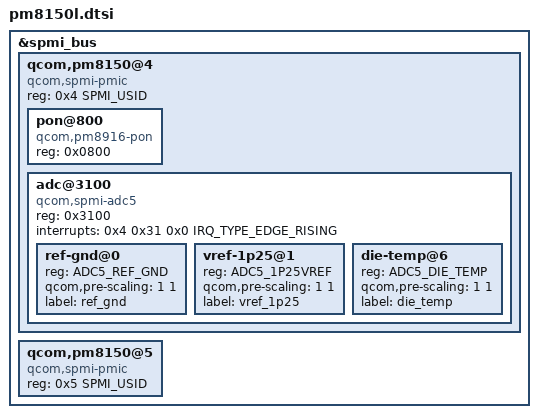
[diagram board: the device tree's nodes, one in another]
// SPDX-License-Identifier: BSD-3-Clause
// Copyright (c) 2017-2019, The Linux Foundation. All rights reserved.
// Copyright (c) 2019, Linaro Limited

#include <dt-bindings/iio/qcom,spmi-vadc.h>
#include <dt-bindings/interrupt-controller/irq.h>
#include <dt-bindings/spmi/spmi.h>

&spmi_bus {
	qcom,pm8150@4 {
		compatible = "qcom,spmi-pmic";
		reg = <0x4 SPMI_USID>;
		#address-cells = <1>;
		#size-cells = <0>;

		pon@800 {
			compatible = "qcom,pm8916-pon";
			reg = <0x0800>;
		};

		adc@3100 {
			compatible = "qcom,spmi-adc5";
			reg = <0x3100>;
			#address-cells = <1>;
			#size-cells = <0>;
			#io-channel-cells = <1>;
			interrupts = <0x4 0x31 0x0 IRQ_TYPE_EDGE_RISING>;

			ref-gnd@0 {
				reg = <ADC5_REF_GND>;
				qcom,pre-scaling = <1 1>;
				label = "ref_gnd";
			};

			vref-1p25@1 {
				reg = <ADC5_1P25VREF>;
				qcom,pre-scaling = <1 1>;
				label = "vref_1p25";
			};

			die-temp@6 {
				reg = <ADC5_DIE_TEMP>;
				qcom,pre-scaling = <1 1>;
				label = "die_temp";
			};
		};
	};

	qcom,pm8150@5 {
		compatible ="qcom,spmi-pmic";
		reg = <0x5 SPMI_USID>;
		#address-cells = <1>;
		#size-cells = <0>;
	};
};
